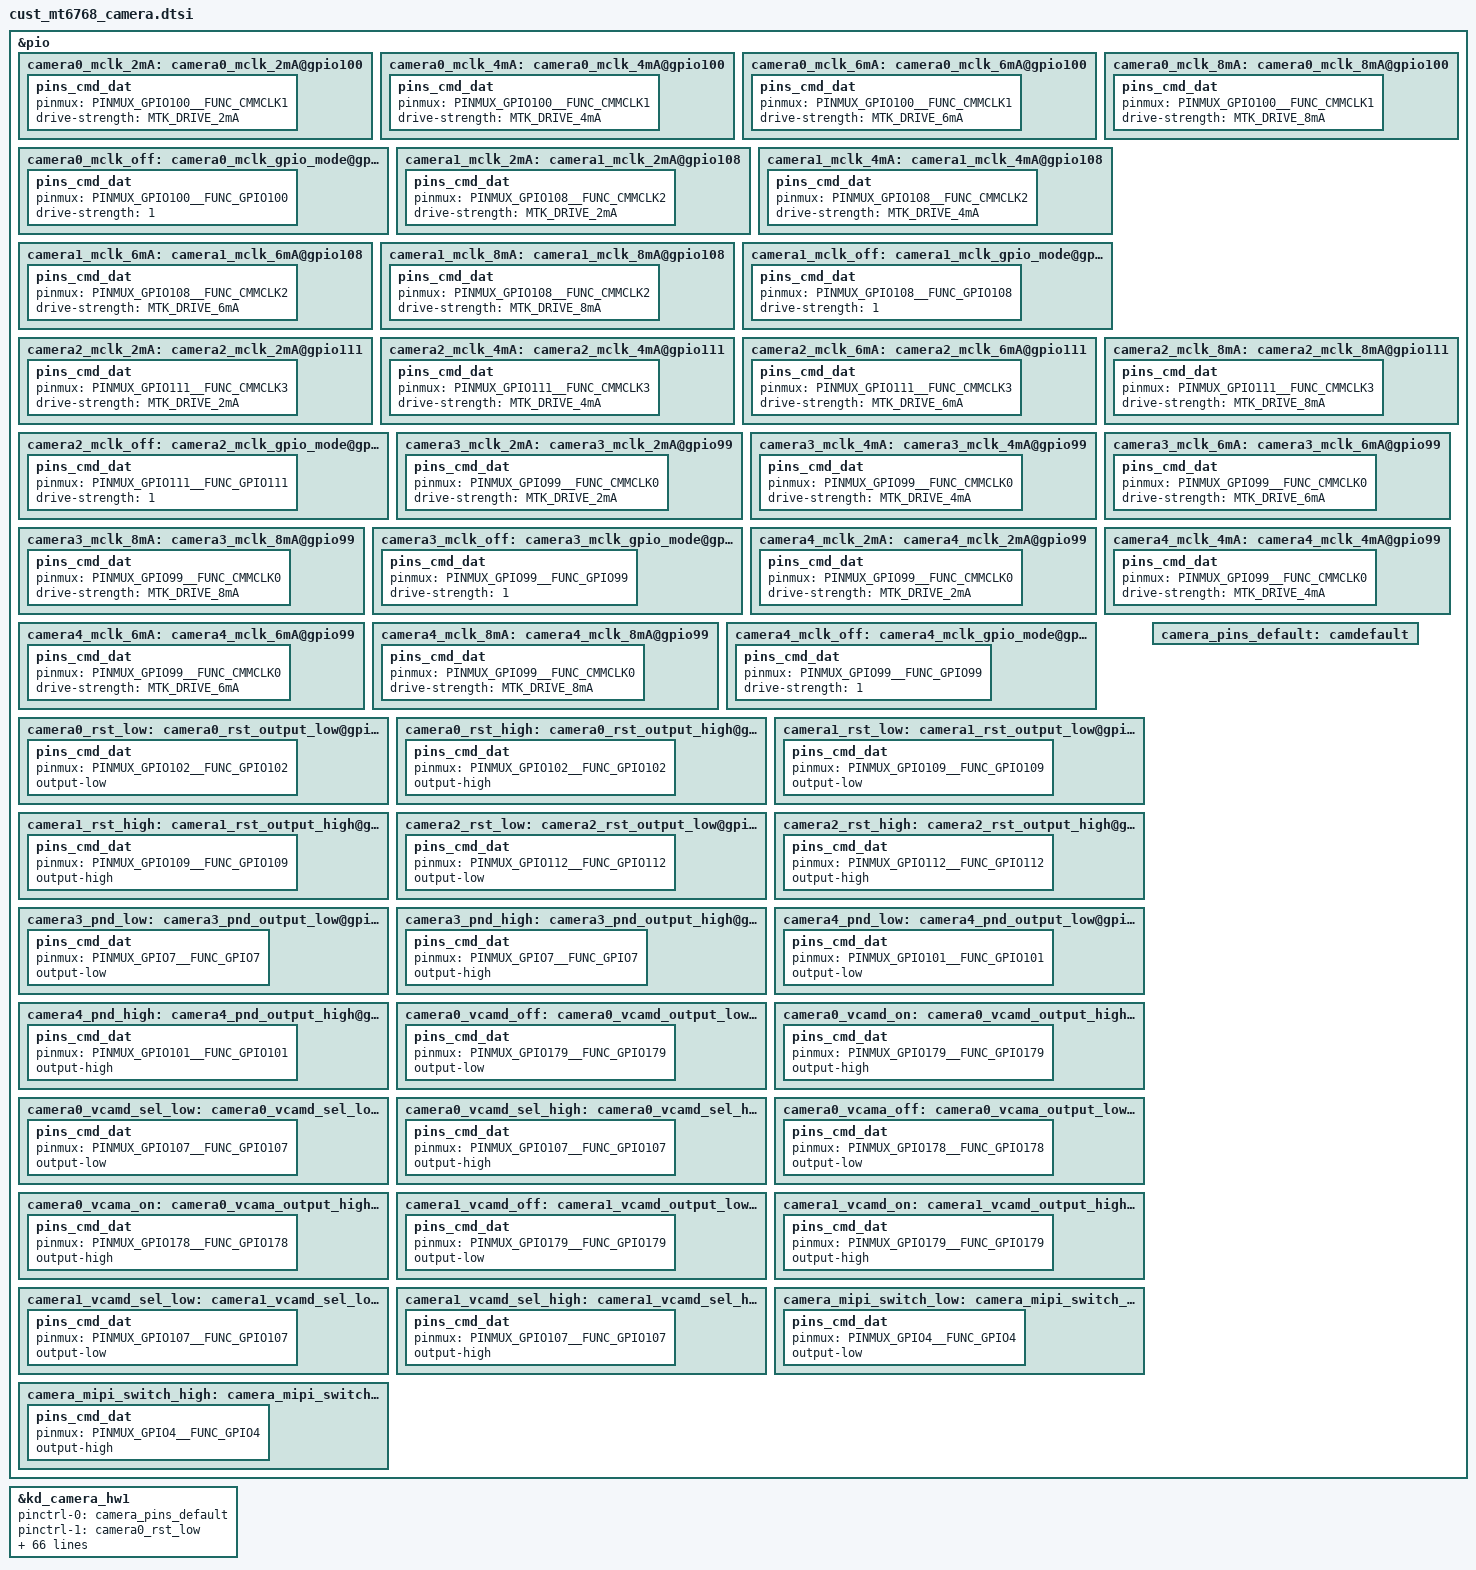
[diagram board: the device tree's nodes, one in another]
/*
 * Copyright (c) 2019 MediaTek Inc.
 *
 * This program is free software; you can redistribute it and/or modify
 * it under the terms of the GNU General Public License version 2 as
 * published by the Free Software Foundation.
 *
 * This program is distributed in the hope that it will be useful,
 * but WITHOUT ANY WARRANTY; without even the implied warranty of
 * MERCHANTABILITY or FITNESS FOR A PARTICULAR PURPOSE.  See the
 * GNU General Public License for more details.
 */
/* CAMERA GPIO standardization */
&pio {
	camera0_mclk_2mA: camera0_mclk_2mA@gpio100 {
		pins_cmd_dat {
			pinmux = <PINMUX_GPIO100__FUNC_CMMCLK1>;
			drive-strength = <MTK_DRIVE_2mA>;
		};
	};
	camera0_mclk_4mA: camera0_mclk_4mA@gpio100 {
		pins_cmd_dat {
			pinmux = <PINMUX_GPIO100__FUNC_CMMCLK1>;
			drive-strength = <MTK_DRIVE_4mA>;
		};
	};
	camera0_mclk_6mA: camera0_mclk_6mA@gpio100 {
		pins_cmd_dat {
			pinmux = <PINMUX_GPIO100__FUNC_CMMCLK1>;
			drive-strength = <MTK_DRIVE_6mA>;
		};
	};
	camera0_mclk_8mA: camera0_mclk_8mA@gpio100 {
		pins_cmd_dat {
			pinmux = <PINMUX_GPIO100__FUNC_CMMCLK1>;
			drive-strength = <MTK_DRIVE_8mA>;
		};
	};
	camera0_mclk_off: camera0_mclk_gpio_mode@gpio100 {
		pins_cmd_dat {
			pinmux = <PINMUX_GPIO100__FUNC_GPIO100>;
			drive-strength = <1>;
		};
	};
	camera1_mclk_2mA: camera1_mclk_2mA@gpio108 {
		pins_cmd_dat {
			pinmux = <PINMUX_GPIO108__FUNC_CMMCLK2>;
			drive-strength = <MTK_DRIVE_2mA>;
		};
	};
	camera1_mclk_4mA: camera1_mclk_4mA@gpio108 {
		pins_cmd_dat {
			pinmux = <PINMUX_GPIO108__FUNC_CMMCLK2>;
			drive-strength = <MTK_DRIVE_4mA>;
		};
	};
	camera1_mclk_6mA: camera1_mclk_6mA@gpio108 {
		pins_cmd_dat {
			pinmux = <PINMUX_GPIO108__FUNC_CMMCLK2>;
			drive-strength = <MTK_DRIVE_6mA>;
		};
	};
	camera1_mclk_8mA: camera1_mclk_8mA@gpio108 {
		pins_cmd_dat {
			pinmux = <PINMUX_GPIO108__FUNC_CMMCLK2>;
			drive-strength = <MTK_DRIVE_8mA>;
		};
	};
	camera1_mclk_off: camera1_mclk_gpio_mode@gpio108 {
		pins_cmd_dat {
			pinmux = <PINMUX_GPIO108__FUNC_GPIO108>;
			drive-strength = <1>;
		};
	};
	camera2_mclk_2mA: camera2_mclk_2mA@gpio111 {
		pins_cmd_dat {
			pinmux = <PINMUX_GPIO111__FUNC_CMMCLK3>;
			drive-strength = <MTK_DRIVE_2mA>;
		};
	};
	camera2_mclk_4mA: camera2_mclk_4mA@gpio111 {
		pins_cmd_dat {
			pinmux = <PINMUX_GPIO111__FUNC_CMMCLK3>;
			drive-strength = <MTK_DRIVE_4mA>;
		};
	};
	camera2_mclk_6mA: camera2_mclk_6mA@gpio111 {
		pins_cmd_dat {
			pinmux = <PINMUX_GPIO111__FUNC_CMMCLK3>;
			drive-strength = <MTK_DRIVE_6mA>;
		};
	};
	camera2_mclk_8mA: camera2_mclk_8mA@gpio111 {
		pins_cmd_dat {
			pinmux = <PINMUX_GPIO111__FUNC_CMMCLK3>;
			drive-strength = <MTK_DRIVE_8mA>;
		};
	};
	camera2_mclk_off: camera2_mclk_gpio_mode@gpio111 {
		pins_cmd_dat {
			pinmux = <PINMUX_GPIO111__FUNC_GPIO111>;
			drive-strength = <1>;
		};
	};
	camera3_mclk_2mA: camera3_mclk_2mA@gpio99 {
		pins_cmd_dat {
			pinmux = <PINMUX_GPIO99__FUNC_CMMCLK0>;
			drive-strength = <MTK_DRIVE_2mA>;
		};
	};
	camera3_mclk_4mA: camera3_mclk_4mA@gpio99 {
		pins_cmd_dat {
			pinmux = <PINMUX_GPIO99__FUNC_CMMCLK0>;
			drive-strength = <MTK_DRIVE_4mA>;
		};
	};
	camera3_mclk_6mA: camera3_mclk_6mA@gpio99 {
		pins_cmd_dat {
			pinmux = <PINMUX_GPIO99__FUNC_CMMCLK0>;
			drive-strength = <MTK_DRIVE_6mA>;
		};
	};
	camera3_mclk_8mA: camera3_mclk_8mA@gpio99 {
		pins_cmd_dat {
			pinmux = <PINMUX_GPIO99__FUNC_CMMCLK0>;
			drive-strength = <MTK_DRIVE_8mA>;
		};
	};
	camera3_mclk_off: camera3_mclk_gpio_mode@gpio99 {
		pins_cmd_dat {
			pinmux = <PINMUX_GPIO99__FUNC_GPIO99>;
			drive-strength = <1>;
		};
	};
	camera4_mclk_2mA: camera4_mclk_2mA@gpio99 {
		pins_cmd_dat {
			pinmux = <PINMUX_GPIO99__FUNC_CMMCLK0>;
			drive-strength = <MTK_DRIVE_2mA>;
		};
	};
	camera4_mclk_4mA: camera4_mclk_4mA@gpio99 {
		pins_cmd_dat {
			pinmux = <PINMUX_GPIO99__FUNC_CMMCLK0>;
			drive-strength = <MTK_DRIVE_4mA>;
		};
	};
	camera4_mclk_6mA: camera4_mclk_6mA@gpio99 {
		pins_cmd_dat {
			pinmux = <PINMUX_GPIO99__FUNC_CMMCLK0>;
			drive-strength = <MTK_DRIVE_6mA>;
		};
	};
	camera4_mclk_8mA: camera4_mclk_8mA@gpio99 {
		pins_cmd_dat {
			pinmux = <PINMUX_GPIO99__FUNC_CMMCLK0>;
			drive-strength = <MTK_DRIVE_8mA>;
		};
	};
	camera4_mclk_off: camera4_mclk_gpio_mode@gpio99 {
		pins_cmd_dat {
			pinmux = <PINMUX_GPIO99__FUNC_GPIO99>;
			drive-strength = <1>;
		};
	};
	camera0_rst_low: camera0_rst_output_low@gpio102 {
		pins_cmd_dat {
			pinmux = <PINMUX_GPIO102__FUNC_GPIO102>;
			output-low;
		};
	};
	camera0_rst_high: camera0_rst_output_high@gpio102 {
		pins_cmd_dat {
			pinmux = <PINMUX_GPIO102__FUNC_GPIO102>;
			output-high;
		};
	};
	camera1_rst_low: camera1_rst_output_low@gpio109 {
		pins_cmd_dat {
			pinmux = <PINMUX_GPIO109__FUNC_GPIO109>;
			output-low;
		};
	};
	camera1_rst_high: camera1_rst_output_high@gpio109 {
		pins_cmd_dat {
			pinmux = <PINMUX_GPIO109__FUNC_GPIO109>;
			output-high;
		};
	};
	camera2_rst_low: camera2_rst_output_low@gpio112 {
		pins_cmd_dat {
			pinmux = <PINMUX_GPIO112__FUNC_GPIO112>;
			output-low;
		};
	};
	camera2_rst_high: camera2_rst_output_high@gpio112 {
		pins_cmd_dat {
			pinmux = <PINMUX_GPIO112__FUNC_GPIO112>;
			output-high;
		};
	};
	camera3_pnd_low: camera3_pnd_output_low@gpio7 {
		pins_cmd_dat {
			pinmux = <PINMUX_GPIO7__FUNC_GPIO7>;
			output-low;
		};
	};
	camera3_pnd_high: camera3_pnd_output_high@gpio7 {
		pins_cmd_dat {
			pinmux = <PINMUX_GPIO7__FUNC_GPIO7>;
			output-high;
		};
	};
	camera4_pnd_low: camera4_pnd_output_low@gpio101 {
		pins_cmd_dat {
			pinmux = <PINMUX_GPIO101__FUNC_GPIO101>;
			output-low;
		};
	};
	camera4_pnd_high: camera4_pnd_output_high@gpio101 {
		pins_cmd_dat {
			pinmux = <PINMUX_GPIO101__FUNC_GPIO101>;
			output-high;
		};
	};
	camera0_vcamd_off: camera0_vcamd_output_low@gpio179 {
		pins_cmd_dat {
			pinmux = <PINMUX_GPIO179__FUNC_GPIO179>;
			output-low;
		};
	};
	camera0_vcamd_on: camera0_vcamd_output_high@gpio179 {
		pins_cmd_dat {
			pinmux = <PINMUX_GPIO179__FUNC_GPIO179>;
			output-high;
		};
	};
	camera0_vcamd_sel_low: camera0_vcamd_sel_low@gpio107 {
		pins_cmd_dat {
			pinmux = <PINMUX_GPIO107__FUNC_GPIO107>;
			output-low;
		};
	};
	camera0_vcamd_sel_high: camera0_vcamd_sel_high@gpio107 {
		pins_cmd_dat {
			pinmux = <PINMUX_GPIO107__FUNC_GPIO107>;
			output-high;
		};
	};
	camera0_vcama_off: camera0_vcama_output_low@gpio178 {
		pins_cmd_dat {
			pinmux = <PINMUX_GPIO178__FUNC_GPIO178>;
			output-low;
		};
	};
	camera0_vcama_on: camera0_vcama_output_high@gpio178 {
		pins_cmd_dat {
			pinmux = <PINMUX_GPIO178__FUNC_GPIO178>;
			output-high;
		};
	};
	camera1_vcamd_off: camera1_vcamd_output_low@gpio179 {
		pins_cmd_dat {
			pinmux = <PINMUX_GPIO179__FUNC_GPIO179>;
			output-low;
		};
	};
	camera1_vcamd_on: camera1_vcamd_output_high@gpio179 {
		pins_cmd_dat {
			pinmux = <PINMUX_GPIO179__FUNC_GPIO179>;
			output-high;
		};
	};
	camera1_vcamd_sel_low: camera1_vcamd_sel_low@gpio107 {
		pins_cmd_dat {
			pinmux = <PINMUX_GPIO107__FUNC_GPIO107>;
			output-low;
		};
	};
	camera1_vcamd_sel_high: camera1_vcamd_sel_high@gpio107 {
		pins_cmd_dat {
			pinmux = <PINMUX_GPIO107__FUNC_GPIO107>;
			output-high;
		};
	};
	camera_mipi_switch_low: camera_mipi_switch_low@gpio4 {
		pins_cmd_dat {
			pinmux = <PINMUX_GPIO4__FUNC_GPIO4>;
			output-low;
		};
	};
	camera_mipi_switch_high: camera_mipi_switch_high@gpio4 {
		pins_cmd_dat {
			pinmux = <PINMUX_GPIO4__FUNC_GPIO4>;
			output-high;
		};
	};
	camera_pins_default: camdefault {
	};
};

&kd_camera_hw1 {
	pinctrl-names = "default",
			"cam0_rst0", "cam0_rst1",
			"cam1_rst0", "cam1_rst1",
			"cam2_rst0", "cam2_rst1",
			"cam3_pnd0", "cam3_pnd1",
			"cam4_pnd0", "cam4_pnd1",
			"cam0_vcama_on", "cam0_vcama_off",
			"cam0_vcamd_on", "cam0_vcamd_off",
			"cam1_vcamd_on", "cam1_vcamd_off",
			"cam0_mclk_off",
			"cam0_mclk_2mA", "cam0_mclk_4mA",
			"cam0_mclk_6mA", "cam0_mclk_8mA",
			"cam1_mclk_off",
			"cam1_mclk_2mA", "cam1_mclk_4mA",
			"cam1_mclk_6mA", "cam1_mclk_8mA",
			"cam2_mclk_off",
			"cam2_mclk_2mA", "cam2_mclk_4mA",
			"cam2_mclk_6mA", "cam2_mclk_8mA",
			"cam3_mclk_off",
			"cam3_mclk_2mA", "cam3_mclk_4mA",
			"cam3_mclk_6mA", "cam3_mclk_8mA",
			"cam4_mclk_off",
			"cam4_mclk_2mA", "cam4_mclk_4mA",
			"cam4_mclk_6mA", "cam4_mclk_8mA",
			"cam_mipi_switch_sel_0", "cam_mipi_switch_sel_1",
			"cam0_vcamd_sel_high", "cam0_vcamd_sel_low",
			"cam1_vcamd_sel_high", "cam1_vcamd_sel_low";

	pinctrl-0 = <&camera_pins_default>;
	pinctrl-1 = <&camera0_rst_low>;
	pinctrl-2 = <&camera0_rst_high>;
	pinctrl-3 = <&camera1_rst_low>;
	pinctrl-4 = <&camera1_rst_high>;
	pinctrl-5 = <&camera2_rst_low>;
	pinctrl-6 = <&camera2_rst_high>;
	pinctrl-7 = <&camera3_pnd_low>;
	pinctrl-8 = <&camera3_pnd_high>;
	pinctrl-9 = <&camera4_pnd_low>;
	pinctrl-10 = <&camera4_pnd_high>;
	pinctrl-11 = <&camera0_vcama_on>;
	pinctrl-12 = <&camera0_vcama_off>;
	pinctrl-13 = <&camera0_vcamd_on>;
	pinctrl-14 = <&camera0_vcamd_off>;
	pinctrl-15 = <&camera1_vcamd_on>;
	pinctrl-16 = <&camera1_vcamd_off>;
	pinctrl-17 = <&camera0_mclk_off>;
	pinctrl-18 = <&camera0_mclk_2mA>;
	pinctrl-19 = <&camera0_mclk_4mA>;
	pinctrl-20 = <&camera0_mclk_6mA>;
	pinctrl-21 = <&camera0_mclk_8mA>;
	pinctrl-22 = <&camera1_mclk_off>;
	pinctrl-23 = <&camera1_mclk_2mA>;
	pinctrl-24 = <&camera1_mclk_4mA>;
	pinctrl-25 = <&camera1_mclk_6mA>;
	pinctrl-26 = <&camera1_mclk_8mA>;
	pinctrl-27 = <&camera2_mclk_off>;
	pinctrl-28 = <&camera2_mclk_2mA>;
	pinctrl-29 = <&camera2_mclk_4mA>;
	pinctrl-30 = <&camera2_mclk_6mA>;
	pinctrl-31 = <&camera2_mclk_8mA>;
	pinctrl-32 = <&camera3_mclk_off>;
	pinctrl-33 = <&camera3_mclk_2mA>;
	pinctrl-34 = <&camera3_mclk_4mA>;
	pinctrl-35 = <&camera3_mclk_6mA>;
	pinctrl-36 = <&camera3_mclk_8mA>;
	pinctrl-37 = <&camera4_mclk_off>;
	pinctrl-38 = <&camera4_mclk_2mA>;
	pinctrl-39 = <&camera4_mclk_4mA>;
	pinctrl-40 = <&camera4_mclk_6mA>;
	pinctrl-41 = <&camera4_mclk_8mA>;
	pinctrl-42 = <&camera_mipi_switch_low>;
	pinctrl-43 = <&camera_mipi_switch_high>;
	pinctrl-44 = <&camera0_vcamd_sel_high>;
	pinctrl-45 = <&camera0_vcamd_sel_low>;
	pinctrl-46 = <&camera1_vcamd_sel_high>;
	pinctrl-47 = <&camera1_vcamd_sel_low>;

	cam0_vcamaf-supply = <&mt_pmic_vldo28_ldo_reg>;
	cam1_vcama-supply = <&mt_pmic_vcama1_ldo_reg>;
	cam2_vcama-supply = <&mt_pmic_vcama2_ldo_reg>;
	cam3_vcama-supply = <&mt_pmic_vcama2_ldo_reg>;
	cam4_vcama-supply = <&mt_pmic_vcama2_ldo_reg>;
	cam2_vcamd-supply = <&mt_pmic_vcamd_ldo_reg>;
	cam0_vcamio-supply = <&mt_pmic_vcamio_ldo_reg>;
	cam1_vcamio-supply = <&mt_pmic_vcamio_ldo_reg>;
	cam2_vcamio-supply = <&mt_pmic_vcamio_ldo_reg>;
	cam3_vcamio-supply = <&mt_pmic_vcamio_ldo_reg>;
	cam4_vcamio-supply = <&mt_pmic_vcamio_ldo_reg>;

	cam0_enable_sensor = "ov12a10_mipi_raw ov13b10_mipi_raw s5kgm1sp_mipi_raw";
	cam1_enable_sensor = "s5k4h7_mipi_raw s5k3p9sp_mipi_raw";
	cam2_enable_sensor = "ov8856_mipi_raw";
	cam3_enable_sensor = "gc02m0_mipi_mono gc2375h_mipi_raw";
	cam4_enable_sensor = "gc2375h_mipi_mono gc02m1_mipi_mono";

	status = "okay";

};
/* CAMERA GPIO end */
